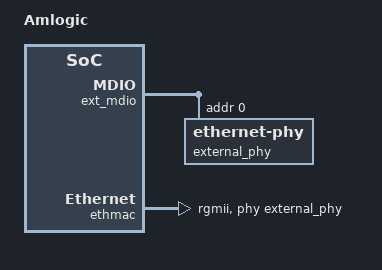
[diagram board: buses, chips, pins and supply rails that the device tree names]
#include "sm1_s905x3_2g.dts"

/ {
	model = "Amlogic";
	coreelec-dt-id = "sm1_s905x3_2g";
};

&ext_mdio {
	external_phy: ethernet-phy@0 {
		reg = <0>;
		max-speed = <1000>;
	};
};

&ethmac {
	pinctrl-0 = <&external_eth_pins>;
	pinctrl-names = "default";
	status = "okay";
	phy-mode = "rgmii";
	phy-handle = <&external_phy>;
	internal_phy = <0>;
	amlogic,tx-delay-ns = <2>;
};
